# HC32M413 register map
File version: 1.0
CPU: CM4 r0p1, little endian, MPU, FPU, 4 interrupt priority bits
Registers are 32-bit, read-write, reset 0x0 unless marked. A register's access mark holds for its fields unless they carry their own. Offsets are from the block's base; [hi:lo] are bit positions; {n}, {i} and the like mark numbered series; 'fields as' and 'values as' point back to an identical list.

## GPIO
Base 0x40053800
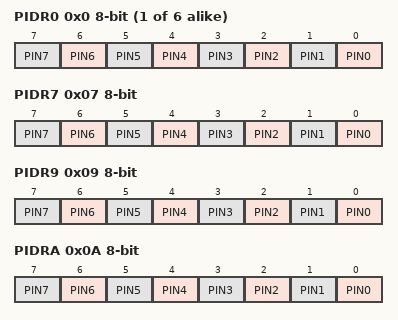
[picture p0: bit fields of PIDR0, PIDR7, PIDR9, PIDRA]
{0x0+i} PIDR{i} 8-bit ro (i=0..5)
  [n] PIN{n} (n=0..7)
0x07 PIDR7 8-bit ro
  [n] PIN{n} (n=0..7)
0x09 PIDR9 8-bit ro
  [n] PIN{n} (n=0..7)
0x0A PIDRA 8-bit ro
  [n] PIN{n} (n=0..7)
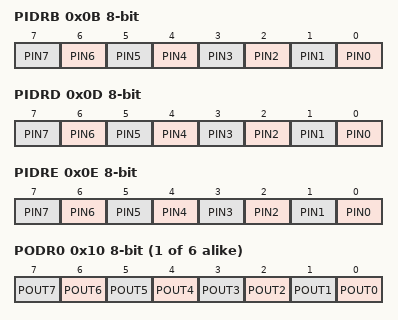
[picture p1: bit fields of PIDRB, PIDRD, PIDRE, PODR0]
0x0B PIDRB 8-bit ro
  [n] PIN{n} (n=0..7)
0x0D PIDRD 8-bit ro
  [n] PIN{n} (n=0..7)
0x0E PIDRE 8-bit ro
  [n] PIN{n} (n=0..7)
{0x10+i} PODR{i} 8-bit (i=0..5)
  [n] POUT{n} (n=0..7)
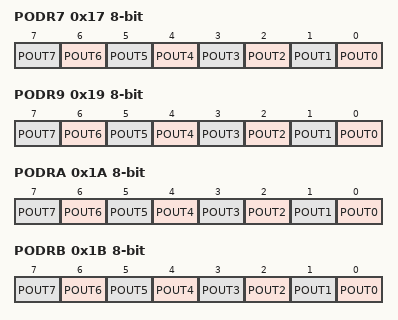
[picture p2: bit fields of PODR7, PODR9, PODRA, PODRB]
0x17 PODR7 8-bit
  [n] POUT{n} (n=0..7)
0x19 PODR9 8-bit
  [n] POUT{n} (n=0..7)
0x1A PODRA 8-bit
  [n] POUT{n} (n=0..7)
0x1B PODRB 8-bit
  [n] POUT{n} (n=0..7)
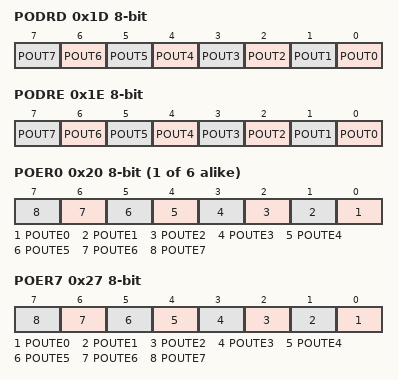
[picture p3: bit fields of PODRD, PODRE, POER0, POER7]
0x1D PODRD 8-bit
  [n] POUT{n} (n=0..7)
0x1E PODRE 8-bit
  [n] POUT{n} (n=0..7)
{0x20+i} POER{i} 8-bit (i=0..5)
  [n] POUTE{n} (n=0..7)
0x27 POER7 8-bit
  [n] POUTE{n} (n=0..7)
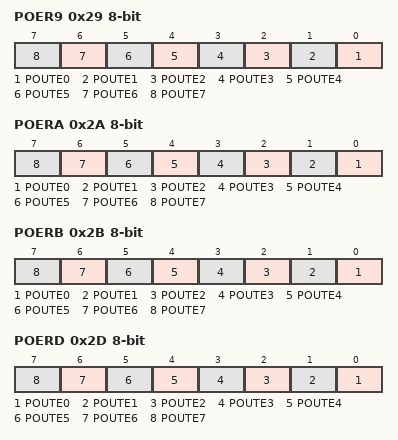
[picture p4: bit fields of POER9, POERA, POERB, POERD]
0x29 POER9 8-bit
  [n] POUTE{n} (n=0..7)
0x2A POERA 8-bit
  [n] POUTE{n} (n=0..7)
0x2B POERB 8-bit
  [n] POUTE{n} (n=0..7)
0x2D POERD 8-bit
  [n] POUTE{n} (n=0..7)
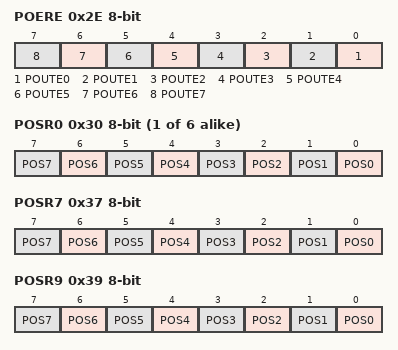
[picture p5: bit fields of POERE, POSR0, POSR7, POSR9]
0x2E POERE 8-bit
  [n] POUTE{n} (n=0..7)
{0x30+i} POSR{i} 8-bit wo (i=0..5)
  [n] POS{n} (n=0..7)
0x37 POSR7 8-bit wo
  [n] POS{n} (n=0..7)
0x39 POSR9 8-bit wo
  [n] POS{n} (n=0..7)
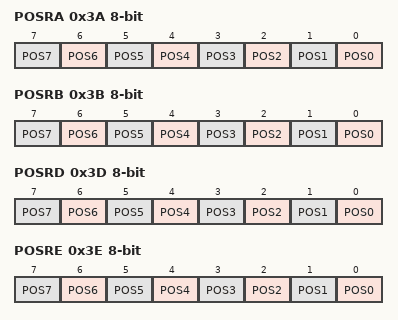
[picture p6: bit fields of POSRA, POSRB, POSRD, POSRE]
0x3A POSRA 8-bit wo
  [n] POS{n} (n=0..7)
0x3B POSRB 8-bit wo
  [n] POS{n} (n=0..7)
0x3D POSRD 8-bit wo
  [n] POS{n} (n=0..7)
0x3E POSRE 8-bit wo
  [n] POS{n} (n=0..7)
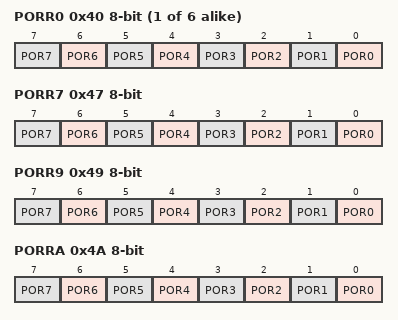
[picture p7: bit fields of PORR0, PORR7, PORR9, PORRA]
{0x40+i} PORR{i} 8-bit wo (reset mask 0x7) (i=0..5)
  [n] POR{n} (n=0..7)
0x47 PORR7 8-bit wo (reset mask 0x7)
  [n] POR{n} (n=0..7)
0x49 PORR9 8-bit wo (reset mask 0x7)
  [n] POR{n} (n=0..7)
0x4A PORRA 8-bit wo (reset mask 0x7)
  [n] POR{n} (n=0..7)
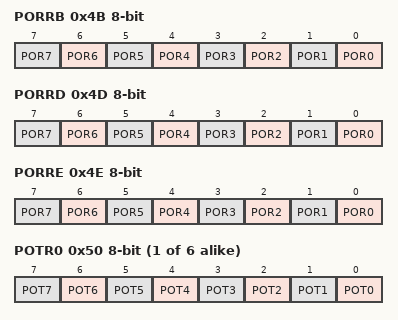
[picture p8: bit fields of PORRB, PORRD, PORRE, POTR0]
0x4B PORRB 8-bit wo (reset mask 0x7)
  [n] POR{n} (n=0..7)
0x4D PORRD 8-bit wo (reset mask 0x7)
  [n] POR{n} (n=0..7)
0x4E PORRE 8-bit wo (reset mask 0x7)
  [n] POR{n} (n=0..7)
{0x50+i} POTR{i} 8-bit wo (i=0..5)
  [n] POT{n} (n=0..7)
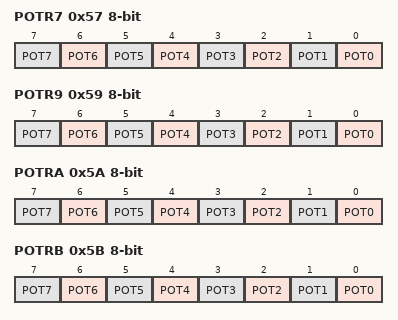
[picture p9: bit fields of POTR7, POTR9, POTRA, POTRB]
0x57 POTR7 8-bit wo
  [n] POT{n} (n=0..7)
0x59 POTR9 8-bit wo
  [n] POT{n} (n=0..7)
0x5A POTRA 8-bit wo
  [n] POT{n} (n=0..7)
0x5B POTRB 8-bit wo
  [n] POT{n} (n=0..7)
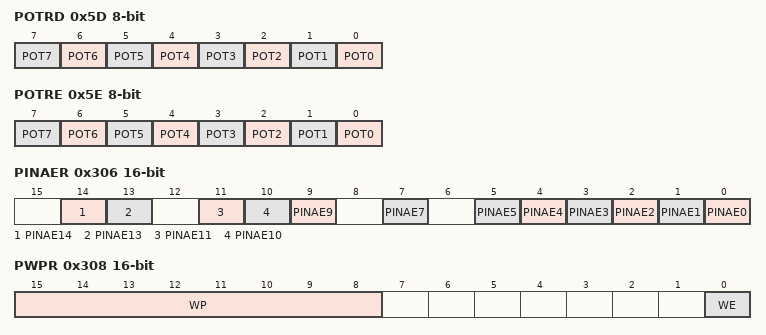
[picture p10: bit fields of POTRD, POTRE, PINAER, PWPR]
0x5D POTRD 8-bit wo
  [n] POT{n} (n=0..7)
0x5E POTRE 8-bit wo
  [n] POT{n} (n=0..7)
0x300 PSPCR 16-bit reset 0x3
  [1:0] SPFE
0x304 PCCR 16-bit reset 0x4000
  [15:14] RDWT
0x306 PINAER 16-bit
  [14] PINAE14, [13] PINAE13, [11] PINAE11, [10] PINAE10, [9] PINAE9, [7] PINAE7, [n] PINAE{n} (n=0..5)
0x308 PWPR 16-bit
  [15:8] WP wo, [0] WE
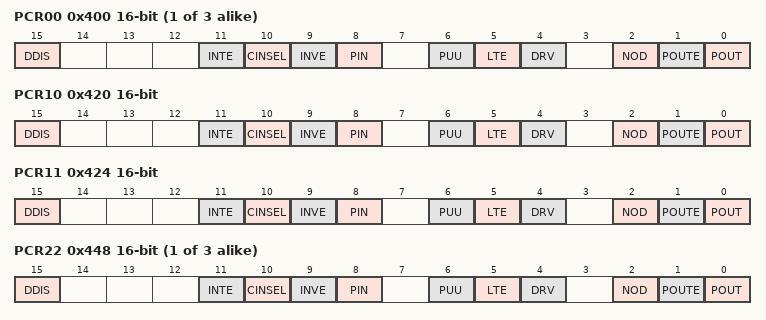
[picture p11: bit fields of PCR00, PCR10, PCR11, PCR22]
{0x400+4i} PCR{i:02} 16-bit (i=0..2)
  [15] DDIS, [11] INTE, [10] CINSEL, [9] INVE, [8] PIN ro, [6] PUU, [5] LTE, [4] DRV, [2] NOD, [1] POUTE, [0] POUT
{0x402+4i} PFSR{i:02} 16-bit (i=0..2)
  [3:0] FSEL
0x420 PCR10 16-bit
  fields as PCR00
0x422 PFSR10 16-bit
  [3:0] FSEL
0x424 PCR11 16-bit
  fields as PCR00
0x426 PFSR11 16-bit
  [3:0] FSEL
{0x3F0+4i} PCR{i} 16-bit (i=22..24)
  fields as PCR00
{0x3F2+4i} PFSR{i} 16-bit (i=22..24)
  [3:0] FSEL
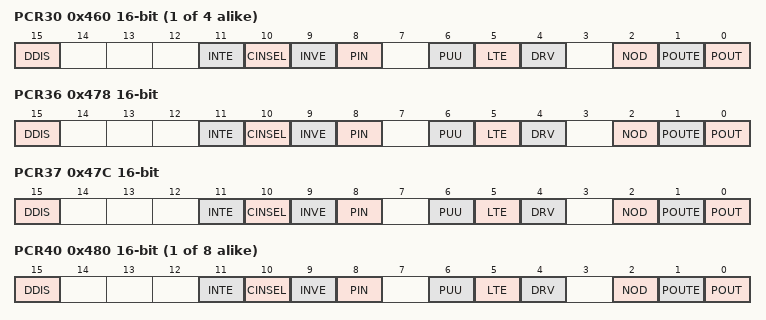
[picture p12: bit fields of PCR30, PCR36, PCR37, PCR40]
{0x3E8+4i} PCR{i} 16-bit (i=30..33)
  fields as PCR00
{0x3EA+4i} PFSR{i} 16-bit (i=30..33)
  [3:0] FSEL
0x478 PCR36 16-bit
  fields as PCR00
0x47A PFSR36 16-bit
  [3:0] FSEL
0x47C PCR37 16-bit
  fields as PCR00
0x47E PFSR37 16-bit
  [3:0] FSEL
{0x3E0+4i} PCR{i} 16-bit (i=40..47)
  fields as PCR00
{0x3E2+4i} PFSR{i} 16-bit (i=40..47)
  [3:0] FSEL
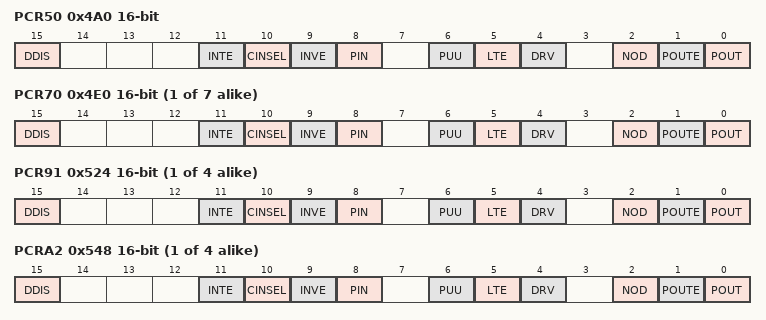
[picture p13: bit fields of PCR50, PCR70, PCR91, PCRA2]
0x4A0 PCR50 16-bit
  fields as PCR00
0x4A2 PFSR50 16-bit
  [3:0] FSEL
{0x3C8+4i} PCR{i} 16-bit (i=70..76)
  fields as PCR00
{0x3CA+4i} PFSR{i} 16-bit (i=70..76)
  [3:0] FSEL
{0x3B8+4i} PCR{i} 16-bit (i=91..94)
  fields as PCR00
{0x3BA+4i} PFSR{i} 16-bit (i=91..94)
  [3:0] FSEL
{0x540+4i} PCRA{i} 16-bit (i=2..5)
  fields as PCR00
{0x542+4i} PFSRA{i} 16-bit (i=2..5)
  [3:0] FSEL
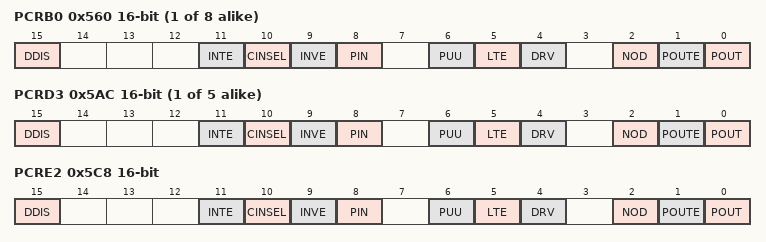
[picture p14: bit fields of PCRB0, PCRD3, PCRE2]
{0x560+4i} PCRB{i} 16-bit (i=0..7)
  fields as PCR00
{0x562+4i} PFSRB{i} 16-bit (i=0..7)
  [3:0] FSEL
{0x5A0+4i} PCRD{i} 16-bit (i=3..7)
  fields as PCR00
{0x5A2+4i} PFSRD{i} 16-bit (i=3..7)
  [3:0] FSEL
0x5C8 PCRE2 16-bit
  fields as PCR00
0x5CA PFSRE2 16-bit
  [3:0] FSEL
